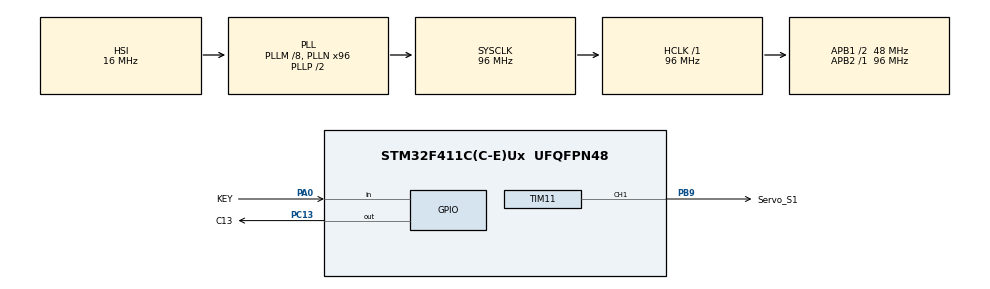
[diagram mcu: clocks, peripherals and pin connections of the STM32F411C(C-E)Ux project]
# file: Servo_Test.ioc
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Mcu.Family=STM32F4
Mcu.Name=STM32F411C(C-E)Ux
Mcu.Package=UFQFPN48
NVIC.PriorityGroup=NVIC_PRIORITYGROUP_4
NVIC.TIM1_TRG_COM_TIM11_IRQn=true\:0\:0\:false\:false\:true\:true\:true
PA0-WKUP.GPIO_Label=KEY
PA0-WKUP.GPIO_PuPd=GPIO_PULLUP
PA0-WKUP.Signal=GPIO_Input
PA13.Mode=Serial_Wire
PA13.Signal=SYS_JTMS-SWDIO
PA14.Mode=Serial_Wire
PA14.Signal=SYS_JTCK-SWCLK
PB9.GPIO_Label=Servo_S1
PB9.Signal=S_TIM11_CH1
PC13-ANTI_TAMP.GPIO_Label=C13
PC13-ANTI_TAMP.PinState=GPIO_PIN_SET
PC13-ANTI_TAMP.Signal=GPIO_Output
PC14-OSC32_IN.Mode=LSE-External-Oscillator
PC14-OSC32_IN.Signal=RCC_OSC32_IN
PC15-OSC32_OUT.Mode=LSE-External-Oscillator
PC15-OSC32_OUT.Signal=RCC_OSC32_OUT
PH0\ -\ OSC_IN.Mode=HSE-External-Oscillator
PH0\ -\ OSC_IN.Signal=RCC_OSC_IN
PH1\ -\ OSC_OUT.Mode=HSE-External-Oscillator
PH1\ -\ OSC_OUT.Signal=RCC_OSC_OUT
ProjectManager.HeapSize=0x200
ProjectManager.StackSize=0x400
ProjectManager.TargetToolchain=MDK-ARM V5.27
RCC.48MHZClocksFreq_Value=48000000
RCC.AHBFreq_Value=96000000
RCC.APB1CLKDivider=RCC_HCLK_DIV2
RCC.APB1Freq_Value=48000000
RCC.APB1TimFreq_Value=96000000
RCC.APB2Freq_Value=96000000
RCC.APB2TimFreq_Value=96000000
RCC.CortexFreq_Value=96000000
RCC.HCLKFreq_Value=96000000
RCC.HSE_VALUE=25000000
RCC.HSI_VALUE=16000000
RCC.PLLM=8
RCC.PLLN=96
RCC.SYSCLKFreq_VALUE=96000000
RCC.SYSCLKSource=RCC_SYSCLKSOURCE_PLLCLK
RCC.VCOOutputFreq_Value=192000000
SH.S_TIM11_CH1.0=TIM11_CH1,PWM Generation1 CH1
TIM11.Channel=TIM_CHANNEL_1
TIM11.Period=20000-1
TIM11.Prescaler=96-1
TIM11.Pulse=1500
VP_RTC_VS_RTC_Activate.Mode=RTC_Enabled
VP_RTC_VS_RTC_Calendar.Mode=RTC_Calendar
VP_TIM11_VS_ClockSourceINT.Mode=Enable_Timer
board=custom

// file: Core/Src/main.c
/* USER CODE BEGIN Header */
/**
  ******************************************************************************
  * @file           : main.c
  * @brief          : Main program body
  ******************************************************************************
  * @attention
  *
  * <h2><center>&copy; Copyright (c) 2019 STMicroelectronics.
  * All rights reserved.</center></h2>
  *
  * This software component is licensed by ST under BSD 3-Clause license,
  * the "License"; You may not use this file except in compliance with the
  * License. You may obtain a copy of the License at:
  *                        opensource.org/licenses/BSD-3-Clause
  *
  ******************************************************************************
  */

// WeAct 工作室 舵机测试
// PB9 5V  GND
// 橙  红  棕
// 按键 PA0/KEY
// 双击启动/关闭舵机
// 单击调速 10°/s ~ 480°/s
// 长按恢复呼吸灯

/* USER CODE END Header */

#include "main.h"
#include "rtc.h"
#include "tim.h"
#include "gpio.h"

/* USER CODE BEGIN Includes */
#include "ServoCtrl.h"
#include "key.h"
/* USER CODE END Includes */

/* USER CODE BEGIN PM */
unsigned short key_value;
uint32_t servo_speed;
/* USER CODE END PM */

void SystemClock_Config(void);

/* USER CODE BEGIN 0 */
 /*
  *power by WeAct Studio
  *The board with `WeAct` Logo && `version number` is our board, quality guarantee.
  *For more information please visit: https://github.com/WeActTC/MiniF4-STM32F4x1
  *更多信息请访问：https://gitee.com/WeActTC/MiniF4-STM32F4x1
  */
/* USER CODE END 0 */

int main(void)
{
  /* USER CODE BEGIN 1 */

  uint32_t tick,tick1,tick2,tick3;
	uint8_t breathsw = 1;
	uint8_t Servosw = 1;
  /* USER CODE END 1 */

  /* MCU Configuration--------------------------------------------------------*/

  /* Reset of all peripherals, Initializes the Flash interface and the Systick. */
  HAL_Init();

  /* Configure the system clock */
  SystemClock_Config();

  /* Initialize all configured peripherals */
  MX_GPIO_Init();
  MX_RTC_Init();
  MX_TIM11_Init();
  /* USER CODE BEGIN 2 */
	ServoCtrlInit();
	HAL_TIM_PWM_Start_IT(&htim11,TIM_CHANNEL_1);

  /* USER CODE END 2 */

  /* Infinite loop */
  while (1)
  {

    /* USER CODE BEGIN 3 */
	  /* C13 呼吸灯测试 */
	  /* C13 Breathing Lamp test */
		static uint8_t pwmset;
		static uint16_t time;
		static uint8_t timeflag;
		static uint8_t timecount;
	  if((HAL_GetTick() - tick >= 1 ))
	  {
		   tick = HAL_GetTick();

		   if(breathsw == 1)
			{
				 /* 呼吸灯 */
				 /* Breathing Lamp */
				if(timeflag == 0)
				{
					time ++;
					if(time >= 1600) timeflag = 1;
				}
				else
				{
					time --;
					if(time == 0) timeflag = 0;
				}

				/* 占空比设置 */
				/* Duty Cycle Setting */
				pwmset = time/80;

				/* 20ms 脉宽 */
				/* 20ms Pulse Width */
				if(timecount > 20) timecount = 0;
				else timecount ++;

				if(timecount >= pwmset ) HAL_GPIO_WritePin(C13_GPIO_Port,C13_Pin,GPIO_PIN_SET);
				else HAL_GPIO_WritePin(C13_GPIO_Port,C13_Pin,GPIO_PIN_RESET);
			}
		}

	  /* 1ms 按键扫描 */
	  if(HAL_GetTick() - tick2 >= 1)
	  {
		  tick2 = HAL_GetTick();
		  key_check_all_loop_1ms();
	  }

	  /* Key按键按下查询 */
	  if(HAL_GetTick() - tick3 >= 10)
	  {
		  tick3 = HAL_GetTick();
		  key_value = key_read_value();

		  if(key_value == KEY0_UP_SHORT)
		  {
				if(Servosw == 1)
				{
					breathsw = 0;

					servo_speed = ServoCtrlS1.ServoSpeed + 40;
					if(servo_speed > 480) servo_speed = 10;
					ServoCtrlS1.ServoSpeed = servo_speed;

					HAL_GPIO_WritePin(C13_GPIO_Port,C13_Pin,GPIO_PIN_RESET);
				}
			  //HAL_GPIO_WritePin(C13_GPIO_Port,C13_Pin,HAL_GPIO_ReadPin(C13_GPIO_Port,C13_Pin)==GPIO_PIN_SET?GPIO_PIN_RESET:GPIO_PIN_SET);

		  }
		  else if(key_value == KEY0_UP_DOUBLE)
		  {
			  breathsw = 0;

				Servosw = Servosw == 1?0:1;

				if(Servosw == 1)
					HAL_GPIO_WritePin(C13_GPIO_Port,C13_Pin,GPIO_PIN_RESET);
				else
				{
					ServoCtrlS1.ServoAngleSet = ServoCtrlS1.ServoAngleNow;
					HAL_GPIO_WritePin(C13_GPIO_Port,C13_Pin,GPIO_PIN_SET);
				}
			  //HAL_GPIO_WritePin(C13_GPIO_Port,C13_Pin,HAL_GPIO_ReadPin(C13_GPIO_Port,C13_Pin)==GPIO_PIN_SET?GPIO_PIN_RESET:GPIO_PIN_SET);
		  }
		  else if(key_value == KEY0_LONG)
		  {
			  breathsw = 1;
		  }

			if(ServoCtrlS1.ServoAngleNow == ServoCtrlS1.ServoAngleSet && Servosw == 1)
			{
				if(ServoCtrlS1.ServoAngleSet >= 90)
					ServoCtrlS1.ServoAngleSet = 0;
				else ServoCtrlS1.ServoAngleSet = 180;
			}
	  }

  }
  /* USER CODE END 3 */
}

void SystemClock_Config(void)
{
  RCC_OscInitTypeDef RCC_OscInitStruct = {0};
  RCC_ClkInitTypeDef RCC_ClkInitStruct = {0};
  RCC_PeriphCLKInitTypeDef PeriphClkInitStruct = {0};

  /** Configure the main internal regulator output voltage
  */
  __HAL_RCC_PWR_CLK_ENABLE();
  __HAL_PWR_VOLTAGESCALING_CONFIG(PWR_REGULATOR_VOLTAGE_SCALE1);
  /** Initializes the CPU, AHB and APB busses clocks
  */
  RCC_OscInitStruct.OscillatorType = RCC_OSCILLATORTYPE_HSI|RCC_OSCILLATORTYPE_LSI;
  RCC_OscInitStruct.HSIState = RCC_HSI_ON;
  RCC_OscInitStruct.HSICalibrationValue = RCC_HSICALIBRATION_DEFAULT;
  RCC_OscInitStruct.LSIState = RCC_LSI_ON;
  RCC_OscInitStruct.PLL.PLLState = RCC_PLL_ON;
  RCC_OscInitStruct.PLL.PLLSource = RCC_PLLSOURCE_HSI;
  RCC_OscInitStruct.PLL.PLLM = 8;
  RCC_OscInitStruct.PLL.PLLN = 96;
  RCC_OscInitStruct.PLL.PLLP = RCC_PLLP_DIV2;
  RCC_OscInitStruct.PLL.PLLQ = 4;
  if (HAL_RCC_OscConfig(&RCC_OscInitStruct) != HAL_OK)
  {
    Error_Handler();
  }
  /** Initializes the CPU, AHB and APB busses clocks
  */
  RCC_ClkInitStruct.ClockType = RCC_CLOCKTYPE_HCLK|RCC_CLOCKTYPE_SYSCLK
                              |RCC_CLOCKTYPE_PCLK1|RCC_CLOCKTYPE_PCLK2;
  RCC_ClkInitStruct.SYSCLKSource = RCC_SYSCLKSOURCE_PLLCLK;
  RCC_ClkInitStruct.AHBCLKDivider = RCC_SYSCLK_DIV1;
  RCC_ClkInitStruct.APB1CLKDivider = RCC_HCLK_DIV2;
  RCC_ClkInitStruct.APB2CLKDivider = RCC_HCLK_DIV1;

  if (HAL_RCC_ClockConfig(&RCC_ClkInitStruct, FLASH_LATENCY_3) != HAL_OK)
  {
    Error_Handler();
  }
  PeriphClkInitStruct.PeriphClockSelection = RCC_PERIPHCLK_RTC;
  PeriphClkInitStruct.RTCClockSelection = RCC_RTCCLKSOURCE_LSI;
  if (HAL_RCCEx_PeriphCLKConfig(&PeriphClkInitStruct) != HAL_OK)
  {
    Error_Handler();
  }
}

void Error_Handler(void)
{
}

/************************ (C) COPYRIGHT STMicroelectronics *****END OF FILE****/
